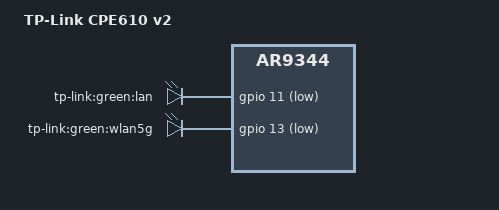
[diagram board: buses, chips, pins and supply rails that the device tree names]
// SPDX-License-Identifier: GPL-2.0-or-later OR MIT

#include "ar9344_tplink_cpe.dtsi"

/ {
	model = "TP-Link CPE610 v2";
	compatible = "tplink,cpe610-v2", "qca,ar9344";

	aliases {
		led-boot = &led_lan;
		led-failsafe = &led_lan;
		led-upgrade = &led_lan;
	};

	leds {
		compatible = "gpio-leds";

		led_lan: lan {
			label = "tp-link:green:lan";
			gpios = <&gpio 11 GPIO_ACTIVE_LOW>;
		};

		wlan5g {
			label = "tp-link:green:wlan5g";
			gpios = <&gpio 13 GPIO_ACTIVE_LOW>;
			linux,default-trigger = "phy0tpt";
		};
	};
};

&eth1 {
	compatible = "syscon", "simple-mfd";
};
